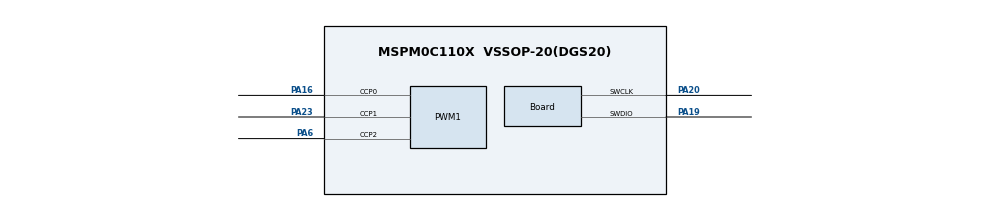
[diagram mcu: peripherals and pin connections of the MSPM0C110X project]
/**
 * @cliArgs --device "MSPM0C110X" --part "Default" --package "VSSOP-20(DGS20)" --product "mspm0_sdk@2.10.00.04"
 * @versions {"tool":"1.26.2+4477"}
 */

/**
 * Import the modules used in this configuration.
 */
const ADC12         = scripting.addModule("/ti/driverlib/ADC12", {}, false);
const ADC121        = ADC12.addInstance();
const Board         = scripting.addModule("/ti/driverlib/Board");
const CAPTURE       = scripting.addModule("/ti/driverlib/CAPTURE", {}, false);
const CAPTURE1      = CAPTURE.addInstance();
const GPIO          = scripting.addModule("/ti/driverlib/GPIO", {}, false);
const GPIO1         = GPIO.addInstance();
const PWM           = scripting.addModule("/ti/driverlib/PWM", {}, false);
const PWM1          = PWM.addInstance();
const SYSCTL        = scripting.addModule("/ti/driverlib/SYSCTL");
const ProjectConfig = scripting.addModule("/ti/project_config/ProjectConfig");

/**
 * Write custom configuration values to the imported modules.
 */
ADC121.$name               = "ADC12_0";
ADC121.adcMem1chansel      = "DL_ADC12_INPUT_CHAN_9";
ADC121.adcMem3chansel      = "DL_ADC12_INPUT_CHAN_2";
ADC121.adcMem2chansel      = "DL_ADC12_INPUT_CHAN_3";
ADC121.sampleTime1         = "100 ns";
ADC121.sampleTime0         = "100 ns";
ADC121.powerDownMode       = "DL_ADC12_POWER_DOWN_MODE_MANUAL";
ADC121.enabledADCMems      = [0,1,2,3];
ADC121.adcMem3_name        = "2";
ADC121.adcMem2_name        = "3";
ADC121.configureDMA        = true;
ADC121.adcPin0Config.$name = "ti_driverlib_gpio_GPIOPinGeneric2";
ADC121.adcPin9Config.$name = "ti_driverlib_gpio_GPIOPinGeneric0";
ADC121.adcPin3Config.$name = "ti_driverlib_gpio_GPIOPinGeneric5";
ADC121.adcPin2Config.$name = "ti_driverlib_gpio_GPIOPinGeneric6";
ADC121.DMA_CHANNEL.$name   = "DMA_CH0";

Board.genPeriphPinFile            = true;
Board.peripheral.swclkPin.$assign = "PA20";
Board.peripheral.swdioPin.$assign = "PA19";
Board.genFileMod.$name            = "ti_driverlib_BoardPins0";

CAPTURE1.$name                       = "CAPTURE_0";
CAPTURE1.captureInputMode            = "multi";
CAPTURE1.ccIndexMulti                = [0,1];
CAPTURE1.multi_ch1_captEdgeDetection = "DL_TIMER_CC_CCOND_TRIG_FALL";
CAPTURE1.multi_countRep              = "DL_TIMER_REPEAT_MODE_ENABLED";
CAPTURE1.multi_ch1_input_mode        = "DL_TIMER_CC_IN_SEL_CCPX_PAIR";
CAPTURE1.multi_countMode             = "DL_TIMER_COUNT_MODE_UP";
CAPTURE1.interrupts                  = ["CC0_UP","CC1_UP"];
CAPTURE1.multi_cvae                  = "DL_TIMER_COUNT_AFTER_EN_ZERO";
CAPTURE1.timerPeriod                 = "2.7 ms";
CAPTURE1.ccp0PinConfig.$name         = "ti_driverlib_gpio_GPIOPinGeneric3";

GPIO1.$name                   = "GPIO_GRP_0";
GPIO1.port                    = "PORTA";
GPIO1.associatedPins[0].$name = "PIN_0";

PWM1.$name                      = "PWM_0";
PWM1.ccIndex                    = [0,1,2];
PWM1.timerCount                 = 1200;
PWM1.interrupts                 = ["LOAD_EVENT","ZERO_EVENT"];
PWM1.PWM_CHANNEL_0.$name        = "ti_driverlib_pwm_PWMTimerCC0";
PWM1.PWM_CHANNEL_1.$name        = "ti_driverlib_pwm_PWMTimerCC1";
PWM1.ccp0PinConfig.$name        = "ti_driverlib_gpio_GPIOPinGeneric4";
PWM1.ccp1PinConfig.$name        = "ti_driverlib_gpio_GPIOPinGeneric1";
PWM1.peripheral.$assign         = "TIMG14";
PWM1.peripheral.ccp0Pin.$assign = "PA16";
PWM1.peripheral.ccp1Pin.$assign = "PA23";
PWM1.peripheral.ccp2Pin.$assign = "PA6";
PWM1.PWM_CHANNEL_2.$name        = "ti_driverlib_pwm_PWMTimerCC3";
PWM1.ccp2PinConfig.$name        = "ti_driverlib_gpio_GPIOPinGeneric7";

SYSCTL.peripheral.$assign = "SYSCTL";

ProjectConfig.genLibMC = true;

/**
 * Pinmux solution for unlocked pins/peripherals. This ensures that minor changes to the automatic solver in a future
 * version of the tool will not impact the pinmux you originally saw.  These lines can be completely deleted in order to
 * re-solve from scratch.
 */
ADC121.peripheral.$suggestSolution             = "ADC0";
ADC121.peripheral.adcPin0.$suggestSolution     = "PA27";
ADC121.peripheral.adcPin9.$suggestSolution     = "PA17";
ADC121.peripheral.adcPin3.$suggestSolution     = "PA24";
ADC121.peripheral.adcPin2.$suggestSolution     = "PA25";
ADC121.DMA_CHANNEL.peripheral.$suggestSolution = "DMA_CH0";
Board.peripheral.$suggestSolution              = "DEBUGSS";
CAPTURE1.peripheral.$suggestSolution           = "TIMA0";
CAPTURE1.peripheral.ccp0Pin.$suggestSolution   = "PA2";
GPIO1.associatedPins[0].pin.$suggestSolution   = "PA26";
